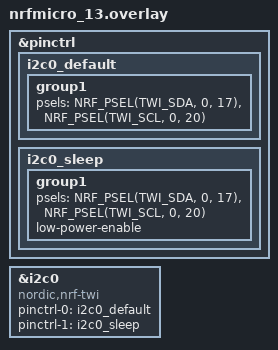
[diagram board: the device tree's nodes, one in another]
&pinctrl {
    i2c0_default: i2c0_default {
        group1 {
            psels = <NRF_PSEL(TWI_SDA, 0, 17)>,
                    <NRF_PSEL(TWI_SCL, 0, 20)>;
        };
    };

    i2c0_sleep: i2c0_sleep {
        group1 {
            psels = <NRF_PSEL(TWI_SDA, 0, 17)>,
                    <NRF_PSEL(TWI_SCL, 0, 20)>;
        low-power-enable;
        };
    };
};

&i2c0 {
    compatible = "nordic,nrf-twi";
    pinctrl-0 = <&i2c0_default>;
    pinctrl-1 = <&i2c0_sleep>;
    pinctrl-names = "default", "sleep";
};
